# earlgrey register map
Vendor: lowRISC; File version: 0.1
CPU: ibex rev01, little endian, no MPU, no FPU, VTOR, 2 interrupt priority bits, 2 interrupts
Registers are 32-bit, read-write, no defined reset value unless marked. A register's access mark holds for its fields unless they carry their own. Offsets are from the block's base; [hi:lo] are bit positions; {n}, {i} and the like mark numbered series; 'fields as' and 'values as' point back to an identical list.

## PINMUX_AON — Multiplexes between on-chip hardware blocks and pins; can be configured at runtime
Base 0x40460000
{0x40+4i} MIO_PERIPH_INSEL_REGWEN_{i} (i=0..32) — Register write enable for MIO peripheral input selects.
  [0] EN — Register write enable bit.If this is cleared to 0, the corresponding MIO_PERIPH_INSELis not writable anymore.
{0xC4+4i} MIO_PERIPH_INSEL_{i} (i=0..32) — For each peripheral input, this selects the muxable pad input.
  [5:0] IN — 0: tie constantly to zero, 1: tie constantly to 1,>=2: MIO pads (i.e., add 2 to the native MIO pad index).
{0x148+4i} MIO_OUTSEL_REGWEN_{i} (i=0..31) — Register write enable for MIO output selects.
  [0] EN — Register write enable bit.If this is cleared to 0, the corresponding MIO_OUTSELis not writable anymore.
{0x1C8+4i} MIO_OUTSEL_{i} (i=0..31) — For each muxable pad, this selects the peripheral output.
  [5:0] OUT — 0: tie constantly to zero, 1: tie constantly to 1, 2: high-Z,>=3: peripheral outputs (i.e., add 3 to the native peripheral pad index).
{0x248+4i} MIO_PAD_ATTR_REGWEN_{i} (i=0..31) — Register write enable for MIO PAD attributes.
  [0] EN — Register write enable bit.If this is cleared to 0, the corresponding !!MIO_PAD_ATTRis not writable anymore.
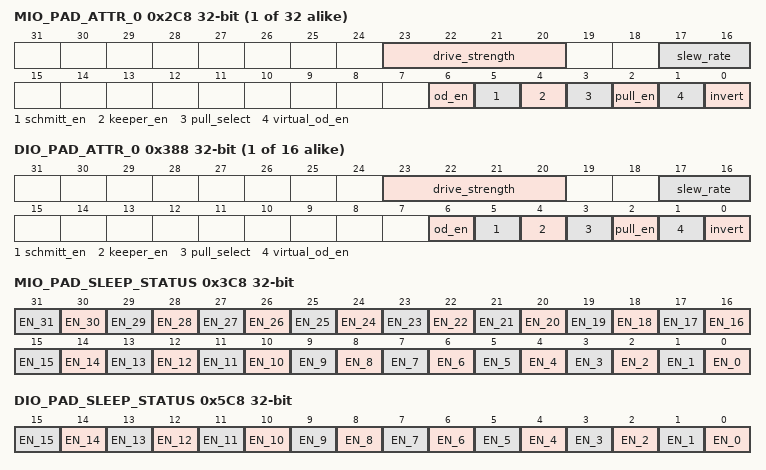
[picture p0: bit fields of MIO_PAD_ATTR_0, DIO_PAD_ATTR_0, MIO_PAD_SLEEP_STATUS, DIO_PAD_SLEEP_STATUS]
{0x2C8+4i} MIO_PAD_ATTR_{i} (i=0..31) — Muxed pad attributes.This register has WARL behavior since not each pad type may supportall attributes.
  [23:20] drive_strength — Drive strength (0x0: weakest, 0xf: strongest)
  [17:16] slew_rate — Slew rate (0x0: slowest, 0x3: fastest).
  [6] od_en — Enable open drain.
  [5] schmitt_en — Enable the schmitt trigger.
  [4] keeper_en — Enable pull-up or pull-down resistor.
  [3] pull_select — Pull select (0: pull-down, 1: pull-up).
  [2] pull_en — Enable pull-up or pull-down resistor.
  [1] virtual_od_en — Enable virtual open drain.
  [0] invert — Invert input and output levels.
{0x348+4i} DIO_PAD_ATTR_REGWEN_{i} (i=0..15) — Register write enable for DIO PAD attributes.
  [0] EN — Register write enable bit.If this is cleared to 0, the corresponding !!DIO_PAD_ATTRis not writable anymore.
{0x388+4i} DIO_PAD_ATTR_{i} (i=0..15) — Dedicated pad attributes.This register has WARL behavior since not each pad type may supportall attributes.
  fields as MIO_PAD_ATTR_0
0x3C8 MIO_PAD_SLEEP_STATUS — Register indicating whether the corresponding pad is in sleep mode.
  [n] EN_{n} (n=0..31) — This register is set to 1 if the deep sleep mode of the correspondingpad has been enabled (!!MIO_PAD_SLEEP_EN) upon deep sleep entry.The sleep mode of the corresponding pad will remain active until SWclears this bit.
{0x448+4i} MIO_PAD_SLEEP_REGWEN_{i} (i=0..31) — Register write enable for MIO sleep value configuration.
  [0] EN — Register write enable bit.If this is cleared to 0, the corresponding !!MIO_OUT_SLEEP_MODEis not writable anymore.
{0x4C8+4i} MIO_PAD_SLEEP_EN_{i} (i=0..31) — Enables the sleep mode of the corresponding muxed pad.
  [0] EN — Deep sleep mode enable.If this bit is set to 1 the corresponding pad will enable the sleep behaviorspecified in !!MIO_PAD_SLEEP_MODE upon deep sleep entry, and the corresponding bitin !!MIO_PAD_SLEEP_STATUS will be set to 1.The pad remains in deep sleep mode until the corresponding bit in!!MIO_PAD_SLEEP_STATUS is cleared by SW.Note that if an always on peripheral is connected to a specific MIO pad,the corresponding !!MIO_PAD_SLEEP_EN bit should be set to 0.
{0x548+4i} MIO_PAD_SLEEP_MODE_{i} (i=0..31) — Defines sleep behavior of the corresponding muxed pad.
  [1:0] OUT — Value to drive in deep sleep.
0x5C8 DIO_PAD_SLEEP_STATUS — Register indicating whether the corresponding pad is in sleep mode.
  [n] EN_{n} (n=0..15) — This register is set to 1 if the deep sleep mode of the correspondingpad has been enabled (!!DIO_PAD_SLEEP_MODE) upon deep sleep entry.The sleep mode of the corresponding pad will remain active until SWclears this bit.
{0x608+4i} DIO_PAD_SLEEP_REGWEN_{i} (i=0..15) — Register write enable for DIO sleep value configuration.
  [0] EN — Register write enable bit.If this is cleared to 0, the corresponding !!DIO_PAD_SLEEP_MODEis not writable anymore.
{0x648+4i} DIO_PAD_SLEEP_EN_{i} (i=0..15) — Enables the sleep mode of the corresponding dedicated pad.
  [0] EN — Deep sleep mode enable.If this bit is set to 1 the corresponding pad will enable the sleep behaviorspecified in !!DIO_PAD_SLEEP_MODE upon deep sleep entry, and the corresponding bitin !!DIO_PAD_SLEEP_STATUS will be set to 1.The pad remains in deep sleep mode until the corresponding bit in!!DIO_PAD_SLEEP_STATUS is cleared by SW.Note that if an always on peripheral is connected to a specific DIO pad,the corresponding !!DIO_PAD_SLEEP_EN bit should be set to 0.
{0x688+4i} DIO_PAD_SLEEP_MODE_{i} (i=0..15) — Defines sleep behavior of the corresponding dedicated pad.
  [1:0] OUT — Value to drive in deep sleep.
{0x6C8+4i} WKUP_DETECTOR_REGWEN_{i} (i=0..7) — Register write enable for wakeup detectors.
  [0] EN — Register write enable bit.If this is cleared to 0, the corresponding WKUP_DETECTORconfiguration is not writable anymore.
{0x6E8+4i} WKUP_DETECTOR_EN_{i} (i=0..7) — Enables for the wakeup detectors.Note that these registers are synced to the always-on clock.The first write access always completes immediately.However, read/write accesses following a write will block until that write has completed.
  [0] EN — Setting this bit activates the corresponding wakeup detector.The behavior is as specified in !!WKUP_DETECTOR,!!WKUP_DETECTOR_CNT_TH and !!WKUP_DETECTOR_PADSEL.
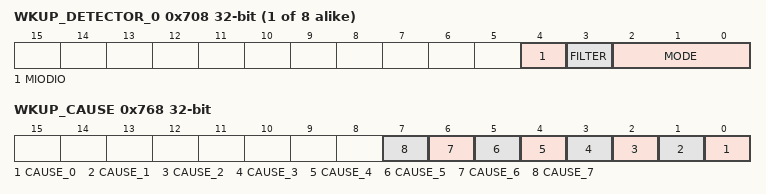
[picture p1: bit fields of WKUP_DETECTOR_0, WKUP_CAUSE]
{0x708+4i} WKUP_DETECTOR_{i} (i=0..7) — Configuration of wakeup condition detectors.Note that these registers are synced to the always-on clock.The first write access always completes immediately.However, read/write accesses following a write will block until that write has completed.Note that the wkup detector should be disabled by setting !!WKUP_DETECTOR_EN_0 before changing the detection mode.The reason for that is that the pulse width counter is NOT cleared upon a mode change while the detector is enabled.
  [4] MIODIO — 0: select index !!WKUP_DETECTOR_PADSEL from MIO pads,1: select index !!WKUP_DETECTOR_PADSEL from DIO pads.
  [3] FILTER — 0: signal filter disabled, 1: signal filter enabled. the signal mustbe stable for 4 always-on clock cycles before the value is being forwarded.can be used for debouncing.
  [2:0] MODE — Wakeup detection mode. Out of range values default to Posedge.
{0x728+4i} WKUP_DETECTOR_CNT_TH_{i} (i=0..7) — Counter thresholds for wakeup condition detectors.Note that these registers are synced to the always-on clock.The first write access always completes immediately.However, read/write accesses following a write will block until that write has completed.
  [7:0] TH — Counter threshold for TimedLow and TimedHigh wakeup detector modes (see !!WKUP_DETECTOR).The threshold is in terms of always-on clock cycles.
{0x748+4i} WKUP_DETECTOR_PADSEL_{i} (i=0..7) — Pad selects for pad wakeup condition detectors.This register is NOT synced to the AON domain since the muxing mechanism is implemented in the same way as the pinmux muxing matrix.
  [5:0] SEL — Selects a specific MIO or DIO pad (depending on !!WKUP_DETECTOR configuration).In case of MIO, the pad select index is the same as used for !!PERIPH_INSEL, meaning that index0 and 1 just select constants 0 and 1, and the MIO pads live at indices >= 2. In case of DIO pads,the pad select index corresponds 1:1 to the DIO pad to be selected.
0x768 WKUP_CAUSE — Cause registers for wakeup detectors.Note that these registers are synced to the always-on clock.The first write access always completes immediately.However, read/write accesses following a write will block until that write has completed.
  [n] CAUSE_{n} (n=0..7) — Set to 1 if the corresponding detector has detected a wakeup pattern. Write 0 to clear.
